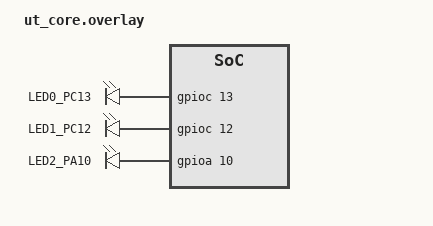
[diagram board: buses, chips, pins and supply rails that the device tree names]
/ {
	pins {
		compatible = "gpio-leds";

		led0: led_0 {
			gpios = <&gpioc 13 GPIO_ACTIVE_HIGH>;
			label = "LED0_PC13";
		};

		led1: led_1 {
			gpios = <&gpioc 12 GPIO_ACTIVE_HIGH>;
			label = "LED1_PC12";
		};

		led2: led_2 {
			gpios = <&gpioa 10 GPIO_ACTIVE_HIGH>;
			label = "LED2_PA10";
		};
	};
};
